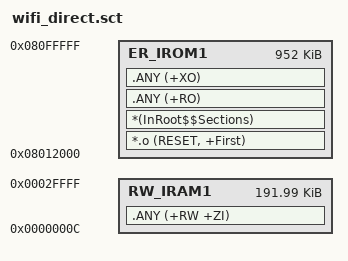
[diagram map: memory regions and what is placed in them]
; *************************************************************
; *** Scatter-Loading Description File generated by uVision ***
; *************************************************************

LR_IROM1 0x08012000 0x000EE000  {    ; load region size_region
  ER_IROM1 0x08012000 0x000EE000  {  ; load address = execution address
   *.o (RESET, +First)
   *(InRoot$$Sections)
   .ANY (+RO)
   .ANY (+XO)
  }
  RW_IRAM1 0x0000000C 0x0002FFF4  {  ; RW data
   .ANY (+RW +ZI)
  }
}

